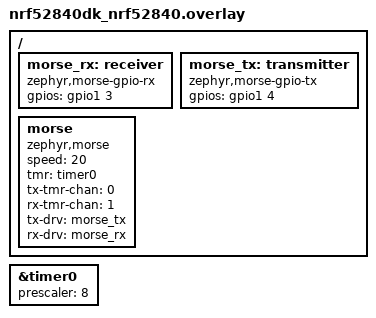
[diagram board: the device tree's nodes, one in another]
/*
 * Copyright (c) 2024-2026 Freedom Veiculos Eletricos
 * Copyright (c) 2024-2026 O.S. Systems Software LTDA.
 *
 * SPDX-License-Identifier: Apache-2.0
 */

/ {
	morse_rx: receiver {
		compatible = "zephyr,morse-gpio-rx";

		gpios = <&gpio1 3 (GPIO_PULL_DOWN | GPIO_ACTIVE_HIGH)>;
	};

	morse_tx: transmitter {
		compatible = "zephyr,morse-gpio-tx";

		gpios = <&gpio1 4 GPIO_ACTIVE_HIGH>;
	};

	morse: morse {
		compatible = "zephyr,morse";
		status = "okay";

		speed = <20>;

		tmr = <&timer0>;

		tx-tmr-chan = <0>;
		rx-tmr-chan = <1>;

		tx-drv = <&morse_tx>;
		rx-drv = <&morse_rx>;
	};
};

&timer0 {
	status = "okay";
	prescaler = <8>;
};
